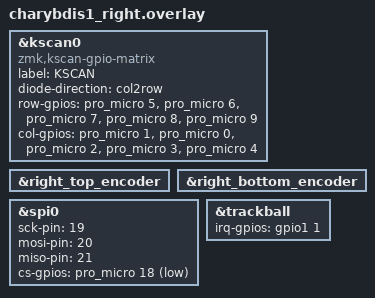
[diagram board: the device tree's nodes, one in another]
#include "charybdis1.dtsi"

&kscan0 {
    compatible = "zmk,kscan-gpio-matrix";
    label = "KSCAN";

    diode-direction = "col2row";
    row-gpios
        = <&pro_micro 5 (GPIO_ACTIVE_HIGH | GPIO_PULL_DOWN)>
        , <&pro_micro 6 (GPIO_ACTIVE_HIGH | GPIO_PULL_DOWN)>
        , <&pro_micro 7 (GPIO_ACTIVE_HIGH | GPIO_PULL_DOWN)>
        , <&pro_micro 8 (GPIO_ACTIVE_HIGH | GPIO_PULL_DOWN)>
        , <&pro_micro 9 (GPIO_ACTIVE_HIGH | GPIO_PULL_DOWN)>
        ;
    
    col-gpios
        = <&pro_micro 1 (GPIO_ACTIVE_HIGH | GPIO_PULL_DOWN)>
        , <&pro_micro 0 (GPIO_ACTIVE_HIGH | GPIO_PULL_DOWN)>
        , <&pro_micro 2 (GPIO_ACTIVE_HIGH | GPIO_PULL_DOWN)>
        , <&pro_micro 3 (GPIO_ACTIVE_HIGH | GPIO_PULL_DOWN)>
        , <&pro_micro 4 (GPIO_ACTIVE_HIGH | GPIO_PULL_DOWN)>
        ;

};

&right_top_encoder {
    status = "okay";
};
&right_bottom_encoder {
    status = "okay";
};

// trackball bus
&spi0 {
	status = "okay"; //okay
	sck-pin = <19>;
	mosi-pin = <20>;
	miso-pin = <21>;
	cs-gpios = <&pro_micro 18 GPIO_ACTIVE_LOW>;
};

&trackball {
	status = "okay"; //okay
	irq-gpios = <&gpio1 1 GPIO_ACTIVE_HIGH>;
};
